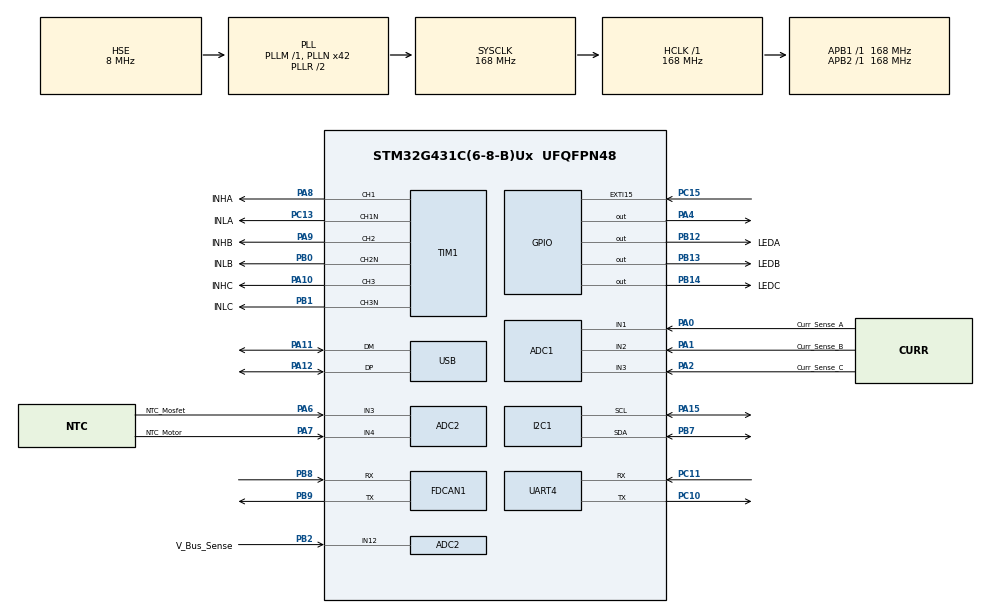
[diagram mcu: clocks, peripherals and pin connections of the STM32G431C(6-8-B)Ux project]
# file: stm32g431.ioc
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ADC1.Channel-6\#ChannelRegularConversion=ADC_CHANNEL_1
ADC1.ClockPrescaler=ADC_CLOCK_ASYNC_DIV1
ADC1.DMAAccessModeView=ENABLE
ADC1.EOCSelection=ADC_EOC_SEQ_CONV
ADC1.EnableInjectedConversion=ENABLE
ADC1.EnableRegularConversion=ENABLE
ADC1.InjNumberOfConversion=3
ADC1.InjectedChannel-2\#ChannelInjectedConversion=ADC_CHANNEL_1
ADC1.InjectedChannel-3\#ChannelInjectedConversion=ADC_CHANNEL_2
ADC1.InjectedChannel-5\#ChannelInjectedConversion=ADC_CHANNEL_3
ADC1.InjectedConvMode=None
ADC1.InjectedOffsetNumber-2\#ChannelInjectedConversion=ADC_OFFSET_NONE
ADC1.InjectedOffsetNumber-3\#ChannelInjectedConversion=ADC_OFFSET_NONE
ADC1.InjectedOffsetNumber-5\#ChannelInjectedConversion=ADC_OFFSET_NONE
ADC1.InjectedRank-2\#ChannelInjectedConversion=1
ADC1.InjectedRank-3\#ChannelInjectedConversion=2
ADC1.InjectedRank-5\#ChannelInjectedConversion=3
ADC1.InjectedSamplingTime-2\#ChannelInjectedConversion=ADC_SAMPLETIME_2CYCLES_5
ADC1.InjectedSamplingTime-3\#ChannelInjectedConversion=ADC_SAMPLETIME_2CYCLES_5
ADC1.InjectedSamplingTime-5\#ChannelInjectedConversion=ADC_SAMPLETIME_2CYCLES_5
ADC1.Mode=ADC_DUALMODE_REGSIMULT_INJECSIMULT
ADC1.NbrOfConversionFlag=1
ADC1.OffsetNumber-6\#ChannelRegularConversion=ADC_OFFSET_NONE
ADC1.Rank-6\#ChannelRegularConversion=1
ADC1.Rank3_Channel=ADC_CHANNEL_3
ADC1.SamplingTime-6\#ChannelRegularConversion=ADC_SAMPLETIME_2CYCLES_5
ADC1.injectedQueueMode=ENABLE
ADC1.master=1
ADC2.Channel-6\#ChannelRegularConversion=ADC_CHANNEL_3
ADC2.Channel-7\#ChannelRegularConversion=ADC_CHANNEL_4
ADC2.Channel-8\#ChannelRegularConversion=ADC_CHANNEL_12
ADC2.ClockPrescaler=ADC_CLOCK_ASYNC_DIV1
ADC2.DMAAccessModeView=ENABLE
ADC2.EnableInjectedConversion=ENABLE
ADC2.EnableRegularConversion=ENABLE
ADC2.InjNumberOfConversion=1
ADC2.InjectedChannel-2\#ChannelInjectedConversion=ADC_CHANNEL_3
ADC2.InjectedOffsetNumber-2\#ChannelInjectedConversion=ADC_OFFSET_NONE
ADC2.InjectedRank-2\#ChannelInjectedConversion=1
ADC2.InjectedSamplingTime-2\#ChannelInjectedConversion=ADC_SAMPLETIME_2CYCLES_5
ADC2.Mode=ADC_DUALMODE_REGSIMULT_INJECSIMULT
ADC2.NbrOfConversion=3
ADC2.NbrOfConversionFlag=1
ADC2.OffsetNumber-6\#ChannelRegularConversion=ADC_OFFSET_NONE
ADC2.OffsetNumber-7\#ChannelRegularConversion=ADC_OFFSET_NONE
ADC2.OffsetNumber-8\#ChannelRegularConversion=ADC_OFFSET_NONE
ADC2.Rank-6\#ChannelRegularConversion=1
ADC2.Rank-7\#ChannelRegularConversion=2
ADC2.Rank-8\#ChannelRegularConversion=3
ADC2.SamplingTime-6\#ChannelRegularConversion=ADC_SAMPLETIME_2CYCLES_5
ADC2.SamplingTime-7\#ChannelRegularConversion=ADC_SAMPLETIME_2CYCLES_5
ADC2.SamplingTime-8\#ChannelRegularConversion=ADC_SAMPLETIME_2CYCLES_5
FDCAN1.CalculateBaudRateNominal=3500000
FDCAN1.CalculateTimeBitNominal=285
FDCAN1.CalculateTimeQuantumNominal=95.23809523809524
FREERTOS.Tasks01=defaultTask,24,128,StartDefaultTask,Default,NULL,Dynamic,NULL,NULL
I2C1.Timing=0x50916E9F
Mcu.Family=STM32G4
Mcu.Name=STM32G431C(6-8-B)Ux
Mcu.Package=UFQFPN48
NVIC.PriorityGroup=NVIC_PRIORITYGROUP_4
NVIC.TIM2_IRQn=true\:15\:0\:false\:false\:true\:false\:false\:true\:true
NVIC.TimeBase=TIM2_IRQn
NVIC.TimeBaseIP=TIM2
NVIC.USB_LP_IRQn=true\:5\:0\:false\:false\:true\:true\:false\:true\:true
PA0.GPIO_Label=Curr_Sense_A
PA0.Mode=IN1-Single-Ended
PA0.Signal=ADC1_IN1
PA1.GPIO_Label=Curr_Sense_B
PA1.Mode=IN2-Single-Ended
PA1.Signal=ADC1_IN2
PA10.GPIO_Label=INHC
PA10.Signal=S_TIM1_CH3
PA11.Mode=Device
PA11.Signal=USB_DM
PA12.Mode=Device
PA12.Signal=USB_DP
PA13.Mode=Serial_Wire
PA13.Signal=SYS_JTMS-SWDIO
PA14.Mode=Serial_Wire
PA14.Signal=SYS_JTCK-SWCLK
PA15.Mode=I2C
PA15.Signal=I2C1_SCL
PA2.GPIO_Label=Curr_Sense_C
PA2.Mode=IN3-Single-Ended
PA2.Signal=ADC1_IN3
PA4.Signal=GPIO_Output
PA6.GPIO_Label=NTC_Mosfet
PA6.Mode=IN3-Single-Ended
PA6.Signal=ADC2_IN3
PA7.GPIO_Label=NTC_Motor
PA7.Mode=IN4-Single-Ended
PA7.Signal=ADC2_IN4
PA8.GPIO_Label=INHA
PA8.Signal=S_TIM1_CH1
PA9.GPIO_Label=INHB
PA9.Signal=S_TIM1_CH2
PB0.GPIO_Label=INLB
PB0.Mode=PWM Generation2 CH2 CH2N
PB0.Signal=TIM1_CH2N
PB1.GPIO_Label=INLC
PB1.Mode=Output Compare3 CH3 CH3N
PB1.Signal=TIM1_CH3N
PB12.GPIO_Label=LEDA
PB12.Signal=GPIO_Output
PB13.GPIO_Label=LEDB
PB13.Signal=GPIO_Output
PB14.GPIO_Label=LEDC
PB14.Signal=GPIO_Output
PB2.GPIO_Label=V_Bus_Sense
PB2.Mode=IN12-Single-Ended
PB2.Signal=ADC2_IN12
PB7.Mode=I2C
PB7.Signal=I2C1_SDA
PB8-BOOT0.Mode=FDCAN_Activate
PB8-BOOT0.Signal=FDCAN1_RX
PB9.Mode=FDCAN_Activate
PB9.Signal=FDCAN1_TX
PC10.Mode=Asynchronous
PC10.Signal=UART4_TX
PC11.Mode=Asynchronous
PC11.Signal=UART4_RX
PC13.GPIO_Label=INLA
PC13.Mode=PWM Generation1 CH1 CH1N
PC13.Signal=TIM1_CH1N
PC15-OSC32_OUT.Signal=GPXTI15
PF0-OSC_IN.Mode=HSE-External-Oscillator
PF0-OSC_IN.Signal=RCC_OSC_IN
PF1-OSC_OUT.Mode=HSE-External-Oscillator
PF1-OSC_OUT.Signal=RCC_OSC_OUT
ProjectManager.HeapSize=0x200
ProjectManager.StackSize=0x400
ProjectManager.TargetToolchain=CMake
RCC.ADC12CLockSelection=RCC_ADC12CLKSOURCE_PLL
RCC.ADC12Freq_Value=48000000
RCC.AHBFreq_Value=168000000
RCC.APB1Freq_Value=168000000
RCC.APB1TimFreq_Value=168000000
RCC.APB2Freq_Value=168000000
RCC.APB2TimFreq_Value=168000000
RCC.CK48CLockSelection=RCC_USBCLKSOURCE_HSI48
RCC.CortexFreq_Value=168000000
RCC.EXTERNAL_CLOCK_VALUE=12288000
RCC.HCLKFreq_Value=168000000
RCC.HSE_VALUE=8000000
RCC.HSI48_VALUE=48000000
RCC.HSI_VALUE=16000000
RCC.LSE_VALUE=32768
RCC.PLLN=42
RCC.PLLP=RCC_PLLP_DIV7
RCC.PLLSourceVirtual=RCC_PLLSOURCE_HSE
RCC.SYSCLKFreq_VALUE=168000000
RCC.SYSCLKSource=RCC_SYSCLKSOURCE_PLLCLK
RCC.USBFreq_Value=48000000
RCC.VCOOutputFreq_Value=336000000
SH.S_TIM1_CH1.0=TIM1_CH1,PWM Generation1 CH1 CH1N
SH.S_TIM1_CH2.0=TIM1_CH2,PWM Generation2 CH2 CH2N
SH.S_TIM1_CH3.0=TIM1_CH3,Output Compare3 CH3 CH3N
TIM1.Channel-Output\ Compare3\ CH3\ CH3N=TIM_CHANNEL_3
TIM1.Channel-PWM\ Generation1\ CH1\ CH1N=TIM_CHANNEL_1
TIM1.Channel-PWM\ Generation2\ CH2\ CH2N=TIM_CHANNEL_2
USB_DEVICE.CLASS_NAME_FS=CDC
USB_DEVICE.VirtualMode=Cdc
USB_DEVICE.VirtualModeFS=Cdc_FS
VP_FREERTOS_VS_CMSIS_V2.Mode=CMSIS_V2
VP_SYS_VS_DBSignals.Mode=DisableDeadBatterySignals
VP_SYS_VS_tim2.Mode=TIM2
VP_TIM1_VS_ClockSourceINT.Mode=Internal
VP_USB_DEVICE_VS_USB_DEVICE_CDC_FS.Mode=CDC_FS
board=custom

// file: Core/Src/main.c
/* USER CODE BEGIN Header */
/**
  ******************************************************************************
  * @file           : main.c
  * @brief          : Main program body
  ******************************************************************************
  * @attention
  *
  * Copyright (c) 2026 STMicroelectronics.
  * All rights reserved.
  *
  * This software is licensed under terms that can be found in the LICENSE file
  * in the root directory of this software component.
  * If no LICENSE file comes with this software, it is provided AS-IS.
  *
  ******************************************************************************
  */
/* USER CODE END Header */
#include "main.h"
#include "cmsis_os.h"
#include "usb_device.h"

/* USER CODE BEGIN Includes */
#include "usbd_cdc_if.h"

/* USER CODE END Includes */

ADC_HandleTypeDef hadc1;
ADC_HandleTypeDef hadc2;

FDCAN_HandleTypeDef hfdcan1;

I2C_HandleTypeDef hi2c1;

TIM_HandleTypeDef htim1;

UART_HandleTypeDef huart4;

/* Definitions for defaultTask */
osThreadId_t defaultTaskHandle;
const osThreadAttr_t defaultTask_attributes = {
  .name = "defaultTask",
  .priority = (osPriority_t) osPriorityNormal,
  .stack_size = 128 * 4
};

void SystemClock_Config(void);
static void MX_GPIO_Init(void);
static void MX_ADC1_Init(void);
static void MX_ADC2_Init(void);
static void MX_TIM1_Init(void);
static void MX_FDCAN1_Init(void);
static void MX_I2C1_Init(void);
static void MX_UART4_Init(void);
void StartDefaultTask(void *argument);

int main(void)
{

  /* MCU Configuration--------------------------------------------------------*/

  /* Reset of all peripherals, Initializes the Flash interface and the Systick. */
  HAL_Init();

  /* Configure the system clock */
  SystemClock_Config();

  /* Initialize all configured peripherals */
  MX_GPIO_Init();
  MX_ADC1_Init();
  MX_ADC2_Init();
  MX_TIM1_Init();
  MX_FDCAN1_Init();
  MX_I2C1_Init();
  MX_UART4_Init();

  /* Init scheduler */
  osKernelInitialize();

  /* Create the thread(s) */
  /* creation of defaultTask */
  defaultTaskHandle = osThreadNew(StartDefaultTask, NULL, &defaultTask_attributes);

  /* Start scheduler */
  osKernelStart();

  /* We should never get here as control is now taken by the scheduler */

  /* Infinite loop */
  while (1)
  {

  }
}

void SystemClock_Config(void)
{
  RCC_OscInitTypeDef RCC_OscInitStruct = {0};
  RCC_ClkInitTypeDef RCC_ClkInitStruct = {0};

  /** Configure the main internal regulator output voltage
  */
  HAL_PWREx_ControlVoltageScaling(PWR_REGULATOR_VOLTAGE_SCALE1_BOOST);

  /** Initializes the RCC Oscillators according to the specified parameters
  * in the RCC_OscInitTypeDef structure.
  */
  RCC_OscInitStruct.OscillatorType = RCC_OSCILLATORTYPE_HSI48|RCC_OSCILLATORTYPE_HSE;
  RCC_OscInitStruct.HSEState = RCC_HSE_ON;
  RCC_OscInitStruct.HSI48State = RCC_HSI48_ON;
  RCC_OscInitStruct.PLL.PLLState = RCC_PLL_ON;
  RCC_OscInitStruct.PLL.PLLSource = RCC_PLLSOURCE_HSE;
  RCC_OscInitStruct.PLL.PLLM = RCC_PLLM_DIV1;
  RCC_OscInitStruct.PLL.PLLN = 42;
  RCC_OscInitStruct.PLL.PLLP = RCC_PLLP_DIV7;
  RCC_OscInitStruct.PLL.PLLQ = RCC_PLLQ_DIV2;
  RCC_OscInitStruct.PLL.PLLR = RCC_PLLR_DIV2;
  if (HAL_RCC_OscConfig(&RCC_OscInitStruct) != HAL_OK)
  {
    Error_Handler();
  }

  /** Initializes the CPU, AHB and APB buses clocks
  */
  RCC_ClkInitStruct.ClockType = RCC_CLOCKTYPE_HCLK|RCC_CLOCKTYPE_SYSCLK
                              |RCC_CLOCKTYPE_PCLK1|RCC_CLOCKTYPE_PCLK2;
  RCC_ClkInitStruct.SYSCLKSource = RCC_SYSCLKSOURCE_PLLCLK;
  RCC_ClkInitStruct.AHBCLKDivider = RCC_SYSCLK_DIV1;
  RCC_ClkInitStruct.APB1CLKDivider = RCC_HCLK_DIV1;
  RCC_ClkInitStruct.APB2CLKDivider = RCC_HCLK_DIV1;

  if (HAL_RCC_ClockConfig(&RCC_ClkInitStruct, FLASH_LATENCY_4) != HAL_OK)
  {
    Error_Handler();
  }
}

static void MX_ADC1_Init(void)
{

  ADC_MultiModeTypeDef multimode = {0};
  ADC_InjectionConfTypeDef sConfigInjected = {0};
  ADC_ChannelConfTypeDef sConfig = {0};

  /** Common config
  */
  hadc1.Instance = ADC1;
  hadc1.Init.ClockPrescaler = ADC_CLOCK_ASYNC_DIV1;
  hadc1.Init.Resolution = ADC_RESOLUTION_12B;
  hadc1.Init.DataAlign = ADC_DATAALIGN_RIGHT;
  hadc1.Init.GainCompensation = 0;
  hadc1.Init.ScanConvMode = ADC_SCAN_ENABLE;
  hadc1.Init.EOCSelection = ADC_EOC_SEQ_CONV;
  hadc1.Init.LowPowerAutoWait = DISABLE;
  hadc1.Init.ContinuousConvMode = DISABLE;
  hadc1.Init.NbrOfConversion = 1;
  hadc1.Init.DiscontinuousConvMode = DISABLE;
  hadc1.Init.ExternalTrigConv = ADC_SOFTWARE_START;
  hadc1.Init.ExternalTrigConvEdge = ADC_EXTERNALTRIGCONVEDGE_NONE;
  hadc1.Init.DMAContinuousRequests = DISABLE;
  hadc1.Init.Overrun = ADC_OVR_DATA_PRESERVED;
  hadc1.Init.OversamplingMode = DISABLE;
  if (HAL_ADC_Init(&hadc1) != HAL_OK)
  {
    Error_Handler();
  }

  /** Configure the ADC multi-mode
  */
  multimode.Mode = ADC_DUALMODE_REGSIMULT_INJECSIMULT;
  multimode.DMAAccessMode = ADC_DMAACCESSMODE_12_10_BITS;
  multimode.TwoSamplingDelay = ADC_TWOSAMPLINGDELAY_1CYCLE;
  if (HAL_ADCEx_MultiModeConfigChannel(&hadc1, &multimode) != HAL_OK)
  {
    Error_Handler();
  }

  /** Configure Injected Channel
  */
  sConfigInjected.InjectedChannel = ADC_CHANNEL_1;
  sConfigInjected.InjectedRank = ADC_INJECTED_RANK_1;
  sConfigInjected.InjectedSamplingTime = ADC_SAMPLETIME_2CYCLES_5;
  sConfigInjected.InjectedSingleDiff = ADC_SINGLE_ENDED;
  sConfigInjected.InjectedOffsetNumber = ADC_OFFSET_NONE;
  sConfigInjected.InjectedOffset = 0;
  sConfigInjected.InjectedNbrOfConversion = 3;
  sConfigInjected.InjectedDiscontinuousConvMode = DISABLE;
  sConfigInjected.AutoInjectedConv = DISABLE;
  sConfigInjected.QueueInjectedContext = DISABLE;
  sConfigInjected.ExternalTrigInjecConv = ADC_EXTERNALTRIGINJEC_EXT_IT15;
  sConfigInjected.ExternalTrigInjecConvEdge = ADC_EXTERNALTRIGINJECCONV_EDGE_RISING;
  sConfigInjected.InjecOversamplingMode = DISABLE;
  if (HAL_ADCEx_InjectedConfigChannel(&hadc1, &sConfigInjected) != HAL_OK)
  {
    Error_Handler();
  }
  if (HAL_ADCEx_EnableInjectedQueue(&hadc1) != HAL_OK)
  {
    Error_Handler();
  }

  /** Configure Injected Channel
  */
  sConfigInjected.InjectedChannel = ADC_CHANNEL_2;
  sConfigInjected.InjectedRank = ADC_INJECTED_RANK_2;
  if (HAL_ADCEx_InjectedConfigChannel(&hadc1, &sConfigInjected) != HAL_OK)
  {
    Error_Handler();
  }

  /** Configure Injected Channel
  */
  sConfigInjected.InjectedChannel = ADC_CHANNEL_3;
  sConfigInjected.InjectedRank = ADC_INJECTED_RANK_3;
  if (HAL_ADCEx_InjectedConfigChannel(&hadc1, &sConfigInjected) != HAL_OK)
  {
    Error_Handler();
  }

  /** Configure Regular Channel
  */
  sConfig.Channel = ADC_CHANNEL_1;
  sConfig.Rank = ADC_REGULAR_RANK_1;
  sConfig.SamplingTime = ADC_SAMPLETIME_2CYCLES_5;
  sConfig.SingleDiff = ADC_SINGLE_ENDED;
  sConfig.OffsetNumber = ADC_OFFSET_NONE;
  sConfig.Offset = 0;
  if (HAL_ADC_ConfigChannel(&hadc1, &sConfig) != HAL_OK)
  {
    Error_Handler();
  }

}

static void MX_ADC2_Init(void)
{

  ADC_InjectionConfTypeDef sConfigInjected = {0};
  ADC_ChannelConfTypeDef sConfig = {0};

  /** Common config
  */
  hadc2.Instance = ADC2;
  hadc2.Init.ClockPrescaler = ADC_CLOCK_ASYNC_DIV1;
  hadc2.Init.Resolution = ADC_RESOLUTION_12B;
  hadc2.Init.DataAlign = ADC_DATAALIGN_RIGHT;
  hadc2.Init.GainCompensation = 0;
  hadc2.Init.ScanConvMode = ADC_SCAN_ENABLE;
  hadc2.Init.EOCSelection = ADC_EOC_SINGLE_CONV;
  hadc2.Init.LowPowerAutoWait = DISABLE;
  hadc2.Init.ContinuousConvMode = DISABLE;
  hadc2.Init.NbrOfConversion = 3;
  hadc2.Init.DiscontinuousConvMode = DISABLE;
  hadc2.Init.DMAContinuousRequests = DISABLE;
  hadc2.Init.Overrun = ADC_OVR_DATA_PRESERVED;
  hadc2.Init.OversamplingMode = DISABLE;
  if (HAL_ADC_Init(&hadc2) != HAL_OK)
  {
    Error_Handler();
  }

  /** Configure Injected Channel
  */
  sConfigInjected.InjectedChannel = ADC_CHANNEL_3;
  sConfigInjected.InjectedRank = ADC_INJECTED_RANK_1;
  sConfigInjected.InjectedSamplingTime = ADC_SAMPLETIME_2CYCLES_5;
  sConfigInjected.InjectedSingleDiff = ADC_SINGLE_ENDED;
  sConfigInjected.InjectedOffsetNumber = ADC_OFFSET_NONE;
  sConfigInjected.InjectedOffset = 0;
  sConfigInjected.InjectedNbrOfConversion = 1;
  sConfigInjected.InjectedDiscontinuousConvMode = DISABLE;
  sConfigInjected.AutoInjectedConv = DISABLE;
  sConfigInjected.QueueInjectedContext = DISABLE;
  sConfigInjected.InjecOversamplingMode = DISABLE;
  if (HAL_ADCEx_InjectedConfigChannel(&hadc2, &sConfigInjected) != HAL_OK)
  {
    Error_Handler();
  }

  /** Configure Regular Channel
  */
  sConfig.Channel = ADC_CHANNEL_3;
  sConfig.Rank = ADC_REGULAR_RANK_1;
  sConfig.SamplingTime = ADC_SAMPLETIME_2CYCLES_5;
  sConfig.SingleDiff = ADC_SINGLE_ENDED;
  sConfig.OffsetNumber = ADC_OFFSET_NONE;
  sConfig.Offset = 0;
  if (HAL_ADC_ConfigChannel(&hadc2, &sConfig) != HAL_OK)
  {
    Error_Handler();
  }

  /** Configure Regular Channel
  */
  sConfig.Channel = ADC_CHANNEL_4;
  sConfig.Rank = ADC_REGULAR_RANK_2;
  if (HAL_ADC_ConfigChannel(&hadc2, &sConfig) != HAL_OK)
  {
    Error_Handler();
  }

  /** Configure Regular Channel
  */
  sConfig.Channel = ADC_CHANNEL_12;
  sConfig.Rank = ADC_REGULAR_RANK_3;
  if (HAL_ADC_ConfigChannel(&hadc2, &sConfig) != HAL_OK)
  {
    Error_Handler();
  }

}

static void MX_FDCAN1_Init(void)
{

  hfdcan1.Instance = FDCAN1;
  hfdcan1.Init.ClockDivider = FDCAN_CLOCK_DIV1;
  hfdcan1.Init.FrameFormat = FDCAN_FRAME_CLASSIC;
  hfdcan1.Init.Mode = FDCAN_MODE_NORMAL;
  hfdcan1.Init.AutoRetransmission = DISABLE;
  hfdcan1.Init.TransmitPause = DISABLE;
  hfdcan1.Init.ProtocolException = DISABLE;
  hfdcan1.Init.NominalPrescaler = 16;
  hfdcan1.Init.NominalSyncJumpWidth = 1;
  hfdcan1.Init.NominalTimeSeg1 = 1;
  hfdcan1.Init.NominalTimeSeg2 = 1;
  hfdcan1.Init.DataPrescaler = 1;
  hfdcan1.Init.DataSyncJumpWidth = 1;
  hfdcan1.Init.DataTimeSeg1 = 1;
  hfdcan1.Init.DataTimeSeg2 = 1;
  hfdcan1.Init.StdFiltersNbr = 0;
  hfdcan1.Init.ExtFiltersNbr = 0;
  hfdcan1.Init.TxFifoQueueMode = FDCAN_TX_FIFO_OPERATION;
  if (HAL_FDCAN_Init(&hfdcan1) != HAL_OK)
  {
    Error_Handler();
  }

}

static void MX_I2C1_Init(void)
{

  hi2c1.Instance = I2C1;
  hi2c1.Init.Timing = 0x50916E9F;
  hi2c1.Init.OwnAddress1 = 0;
  hi2c1.Init.AddressingMode = I2C_ADDRESSINGMODE_7BIT;
  hi2c1.Init.DualAddressMode = I2C_DUALADDRESS_DISABLE;
  hi2c1.Init.OwnAddress2 = 0;
  hi2c1.Init.OwnAddress2Masks = I2C_OA2_NOMASK;
  hi2c1.Init.GeneralCallMode = I2C_GENERALCALL_DISABLE;
  hi2c1.Init.NoStretchMode = I2C_NOSTRETCH_DISABLE;
  if (HAL_I2C_Init(&hi2c1) != HAL_OK)
  {
    Error_Handler();
  }

  /** Configure Analogue filter
  */
  if (HAL_I2CEx_ConfigAnalogFilter(&hi2c1, I2C_ANALOGFILTER_ENABLE) != HAL_OK)
  {
    Error_Handler();
  }

  /** Configure Digital filter
  */
  if (HAL_I2CEx_ConfigDigitalFilter(&hi2c1, 0) != HAL_OK)
  {
    Error_Handler();
  }

}

static void MX_TIM1_Init(void)
{

  TIM_ClockConfigTypeDef sClockSourceConfig = {0};
  TIM_MasterConfigTypeDef sMasterConfig = {0};
  TIM_OC_InitTypeDef sConfigOC = {0};
  TIM_BreakDeadTimeConfigTypeDef sBreakDeadTimeConfig = {0};

  htim1.Instance = TIM1;
  htim1.Init.Prescaler = 0;
  htim1.Init.CounterMode = TIM_COUNTERMODE_UP;
  htim1.Init.Period = 65535;
  htim1.Init.ClockDivision = TIM_CLOCKDIVISION_DIV1;
  htim1.Init.RepetitionCounter = 0;
  htim1.Init.AutoReloadPreload = TIM_AUTORELOAD_PRELOAD_DISABLE;
  if (HAL_TIM_Base_Init(&htim1) != HAL_OK)
  {
    Error_Handler();
  }
  sClockSourceConfig.ClockSource = TIM_CLOCKSOURCE_INTERNAL;
  if (HAL_TIM_ConfigClockSource(&htim1, &sClockSourceConfig) != HAL_OK)
  {
    Error_Handler();
  }
  if (HAL_TIM_PWM_Init(&htim1) != HAL_OK)
  {
    Error_Handler();
  }
  if (HAL_TIM_OC_Init(&htim1) != HAL_OK)
  {
    Error_Handler();
  }
  sMasterConfig.MasterOutputTrigger = TIM_TRGO_RESET;
  sMasterConfig.MasterOutputTrigger2 = TIM_TRGO2_RESET;
  sMasterConfig.MasterSlaveMode = TIM_MASTERSLAVEMODE_DISABLE;
  if (HAL_TIMEx_MasterConfigSynchronization(&htim1, &sMasterConfig) != HAL_OK)
  {
    Error_Handler();
  }
  sConfigOC.OCMode = TIM_OCMODE_PWM1;
  sConfigOC.Pulse = 0;
  sConfigOC.OCPolarity = TIM_OCPOLARITY_HIGH;
  sConfigOC.OCNPolarity = TIM_OCNPOLARITY_HIGH;
  sConfigOC.OCFastMode = TIM_OCFAST_DISABLE;
  sConfigOC.OCIdleState = TIM_OCIDLESTATE_RESET;
  sConfigOC.OCNIdleState = TIM_OCNIDLESTATE_RESET;
  if (HAL_TIM_PWM_ConfigChannel(&htim1, &sConfigOC, TIM_CHANNEL_1) != HAL_OK)
  {
    Error_Handler();
  }
  if (HAL_TIM_PWM_ConfigChannel(&htim1, &sConfigOC, TIM_CHANNEL_2) != HAL_OK)
  {
    Error_Handler();
  }
  sConfigOC.OCMode = TIM_OCMODE_TIMING;
  if (HAL_TIM_OC_ConfigChannel(&htim1, &sConfigOC, TIM_CHANNEL_3) != HAL_OK)
  {
    Error_Handler();
  }
  sBreakDeadTimeConfig.OffStateRunMode = TIM_OSSR_DISABLE;
  sBreakDeadTimeConfig.OffStateIDLEMode = TIM_OSSI_DISABLE;
  sBreakDeadTimeConfig.LockLevel = TIM_LOCKLEVEL_OFF;
  sBreakDeadTimeConfig.DeadTime = 0;
  sBreakDeadTimeConfig.BreakState = TIM_BREAK_DISABLE;
  sBreakDeadTimeConfig.BreakPolarity = TIM_BREAKPOLARITY_HIGH;
  sBreakDeadTimeConfig.BreakFilter = 0;
  sBreakDeadTimeConfig.BreakAFMode = TIM_BREAK_AFMODE_INPUT;
  sBreakDeadTimeConfig.Break2State = TIM_BREAK2_DISABLE;
  sBreakDeadTimeConfig.Break2Polarity = TIM_BREAK2POLARITY_HIGH;
  sBreakDeadTimeConfig.Break2Filter = 0;
  sBreakDeadTimeConfig.Break2AFMode = TIM_BREAK_AFMODE_INPUT;
  sBreakDeadTimeConfig.AutomaticOutput = TIM_AUTOMATICOUTPUT_DISABLE;
  if (HAL_TIMEx_ConfigBreakDeadTime(&htim1, &sBreakDeadTimeConfig) != HAL_OK)
  {
    Error_Handler();
  }
  HAL_TIM_MspPostInit(&htim1);

}

static void MX_UART4_Init(void)
{

  huart4.Instance = UART4;
  huart4.Init.BaudRate = 115200;
  huart4.Init.WordLength = UART_WORDLENGTH_8B;
  huart4.Init.StopBits = UART_STOPBITS_1;
  huart4.Init.Parity = UART_PARITY_NONE;
  huart4.Init.Mode = UART_MODE_TX_RX;
  huart4.Init.HwFlowCtl = UART_HWCONTROL_NONE;
  huart4.Init.OverSampling = UART_OVERSAMPLING_16;
  huart4.Init.OneBitSampling = UART_ONE_BIT_SAMPLE_DISABLE;
  huart4.Init.ClockPrescaler = UART_PRESCALER_DIV1;
  huart4.AdvancedInit.AdvFeatureInit = UART_ADVFEATURE_NO_INIT;
  if (HAL_UART_Init(&huart4) != HAL_OK)
  {
    Error_Handler();
  }
  if (HAL_UARTEx_SetTxFifoThreshold(&huart4, UART_TXFIFO_THRESHOLD_1_8) != HAL_OK)
  {
    Error_Handler();
  }
  if (HAL_UARTEx_SetRxFifoThreshold(&huart4, UART_RXFIFO_THRESHOLD_1_8) != HAL_OK)
  {
    Error_Handler();
  }
  if (HAL_UARTEx_DisableFifoMode(&huart4) != HAL_OK)
  {
    Error_Handler();
  }

}

static void MX_GPIO_Init(void)
{
  GPIO_InitTypeDef GPIO_InitStruct = {0};

  /* GPIO Ports Clock Enable */
  __HAL_RCC_GPIOC_CLK_ENABLE();
  __HAL_RCC_GPIOF_CLK_ENABLE();
  __HAL_RCC_GPIOA_CLK_ENABLE();
  __HAL_RCC_GPIOB_CLK_ENABLE();

  /*Configure GPIO pin Output Level */
  HAL_GPIO_WritePin(GPIOA, GPIO_PIN_4, GPIO_PIN_RESET);

  /*Configure GPIO pin Output Level */
  HAL_GPIO_WritePin(GPIOB, LEDA_Pin|LEDB_Pin|LEDC_Pin, GPIO_PIN_RESET);

  /*Configure GPIO pin : PC15 */
  GPIO_InitStruct.Pin = GPIO_PIN_15;
  GPIO_InitStruct.Mode = GPIO_MODE_IT_RISING;
  GPIO_InitStruct.Pull = GPIO_NOPULL;
  HAL_GPIO_Init(GPIOC, &GPIO_InitStruct);

  /*Configure GPIO pin : PA4 */
  GPIO_InitStruct.Pin = GPIO_PIN_4;
  GPIO_InitStruct.Mode = GPIO_MODE_OUTPUT_PP;
  GPIO_InitStruct.Pull = GPIO_NOPULL;
  GPIO_InitStruct.Speed = GPIO_SPEED_FREQ_LOW;
  HAL_GPIO_Init(GPIOA, &GPIO_InitStruct);

  /*Configure GPIO pins : LEDA_Pin LEDB_Pin LEDC_Pin */
  GPIO_InitStruct.Pin = LEDA_Pin|LEDB_Pin|LEDC_Pin;
  GPIO_InitStruct.Mode = GPIO_MODE_OUTPUT_PP;
  GPIO_InitStruct.Pull = GPIO_NOPULL;
  GPIO_InitStruct.Speed = GPIO_SPEED_FREQ_LOW;
  HAL_GPIO_Init(GPIOB, &GPIO_InitStruct);

}

void StartDefaultTask(void *argument)
{
  /* init code for USB_Device */
  MX_USB_Device_Init();
  /* USER CODE BEGIN 5 */
  /* Infinite loop */
  for(;;)
  {
		HAL_GPIO_WritePin(LEDC_GPIO_Port, LEDC_Pin, GPIO_PIN_SET);
		osDelay(100);
		HAL_GPIO_WritePin(LEDB_GPIO_Port, LEDB_Pin, GPIO_PIN_RESET);
		osDelay(100);
  }
  /* USER CODE END 5 */
}

void HAL_TIM_PeriodElapsedCallback(TIM_HandleTypeDef *htim)
{
  if (htim->Instance == TIM2)
  {
    HAL_IncTick();
  }
}

void Error_Handler(void)
{
  __disable_irq();
  while (1)
  {
  }
}
